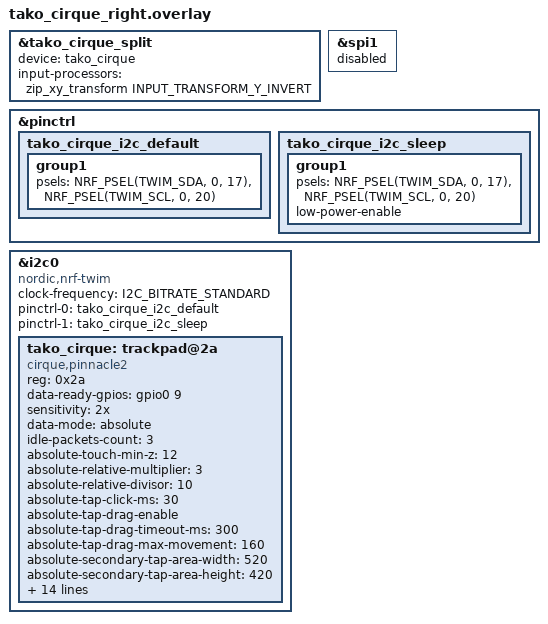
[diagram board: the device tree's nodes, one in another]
/* Add after tako_right, without nice_view/nice_view_custom.
 * Reuse its display socket: MOSI -> SDA, SCK -> SCL, CS -> DR.
 */
#include <zephyr/dt-bindings/gpio/gpio.h>
#include <zephyr/dt-bindings/i2c/i2c.h>
#include <zephyr/dt-bindings/pinctrl/nrf-pinctrl.h>
#include "tako-cirque-split.dtsi"
#include <input/processors/transform.dtsi>
#include <dt-bindings/zmk/input_transform.h>

&tako_cirque_split {
    device = <&tako_cirque>;
    /* The driver ignores invert-y in absolute mode. Transform REL_Y here
     * before BLE forwarding, so both receiver topologies use this direction. */
    input-processors = <&zip_xy_transform INPUT_TRANSFORM_Y_INVERT>;
};

&spi1 {
    status = "disabled";
};

&pinctrl {
    tako_cirque_i2c_default: tako_cirque_i2c_default {
        group1 {
            psels = <NRF_PSEL(TWIM_SDA, 0, 17)>,
                    <NRF_PSEL(TWIM_SCL, 0, 20)>;
        };
    };

    tako_cirque_i2c_sleep: tako_cirque_i2c_sleep {
        group1 {
            psels = <NRF_PSEL(TWIM_SDA, 0, 17)>,
                    <NRF_PSEL(TWIM_SCL, 0, 20)>;
            low-power-enable;
        };
    };
};

&i2c0 {
    compatible = "nordic,nrf-twim";
    status = "okay";
    clock-frequency = <I2C_BITRATE_STANDARD>;
    pinctrl-0 = <&tako_cirque_i2c_default>;
    pinctrl-1 = <&tako_cirque_i2c_sleep>;
    pinctrl-names = "default", "sleep";

    tako_cirque: trackpad@2a {
        compatible = "cirque,pinnacle2";
        reg = <0x2a>;
        status = "okay";
        data-ready-gpios = <&gpio0 9 GPIO_ACTIVE_HIGH>;
        sensitivity = "2x";
        data-mode = "absolute";
        idle-packets-count = <3>;
        absolute-touch-min-z = <12>;
        absolute-relative-multiplier = <3>;
        absolute-relative-divisor = <10>;
        absolute-tap-click-ms = <30>;
        absolute-tap-drag-enable;
        absolute-tap-drag-timeout-ms = <300>;
        absolute-tap-drag-max-movement = <160>;
        absolute-secondary-tap-area-width = <520>;
        absolute-secondary-tap-area-height = <420>;
        absolute-aux-tap-area-width = <0>;
        absolute-aux-tap-area-height = <0>;
        absolute-edge-motion-enable;
        absolute-edge-motion-zone = <80>;
        absolute-edge-motion-speed = <4>;
        absolute-edge-motion-interval-ms = <10>;
        absolute-edge-motion-start-ms = <120>;
        absolute-right-edge-scroll-enable;
        absolute-scroll-zone = <130>;
        absolute-scroll-divisor = <80>;
        startup-delay-ms = <1500>;
        primary-tap-enable;
        glide-extend-enable;
        /* Y inversion is applied by the split processor in both modes. */
        /* Preserve Tako horizontal mounting orientation. */
        invert-x;
    };
};
